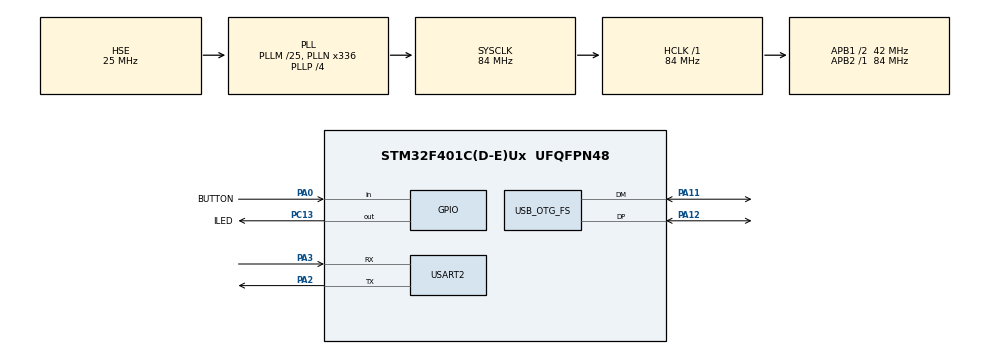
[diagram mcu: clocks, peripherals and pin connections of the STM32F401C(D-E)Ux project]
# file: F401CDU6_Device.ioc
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Dma.Request0=USART2_TX
Dma.Request1=USART2_RX
Dma.USART2_RX.1.Direction=DMA_PERIPH_TO_MEMORY
Dma.USART2_RX.1.FIFOMode=DMA_FIFOMODE_DISABLE
Dma.USART2_RX.1.Instance=DMA1_Stream5
Dma.USART2_RX.1.MemDataAlignment=DMA_MDATAALIGN_BYTE
Dma.USART2_RX.1.MemInc=DMA_MINC_ENABLE
Dma.USART2_RX.1.Mode=DMA_NORMAL
Dma.USART2_RX.1.PeriphDataAlignment=DMA_PDATAALIGN_BYTE
Dma.USART2_RX.1.PeriphInc=DMA_PINC_DISABLE
Dma.USART2_RX.1.Priority=DMA_PRIORITY_VERY_HIGH
Dma.USART2_TX.0.Direction=DMA_MEMORY_TO_PERIPH
Dma.USART2_TX.0.FIFOMode=DMA_FIFOMODE_DISABLE
Dma.USART2_TX.0.Instance=DMA1_Stream6
Dma.USART2_TX.0.MemDataAlignment=DMA_MDATAALIGN_BYTE
Dma.USART2_TX.0.MemInc=DMA_MINC_ENABLE
Dma.USART2_TX.0.Mode=DMA_NORMAL
Dma.USART2_TX.0.PeriphDataAlignment=DMA_PDATAALIGN_BYTE
Dma.USART2_TX.0.PeriphInc=DMA_PINC_DISABLE
Dma.USART2_TX.0.Priority=DMA_PRIORITY_VERY_HIGH
Mcu.Family=STM32F4
Mcu.Name=STM32F401C(D-E)Ux
Mcu.Package=UFQFPN48
NVIC.DMA1_Stream5_IRQn=true\:0\:0\:false\:false\:true\:false\:true\:true
NVIC.DMA1_Stream6_IRQn=true\:0\:0\:false\:false\:true\:false\:true\:true
NVIC.PriorityGroup=NVIC_PRIORITYGROUP_4
NVIC.USART2_IRQn=true\:0\:0\:false\:false\:true\:true\:true\:true
PA0-WKUP.GPIO_Label=BUTTON
PA0-WKUP.Signal=GPIO_Input
PA11.Mode=Device_Only
PA11.Signal=USB_OTG_FS_DM
PA12.Mode=Device_Only
PA12.Signal=USB_OTG_FS_DP
PA13.Mode=Serial_Wire
PA13.Signal=SYS_JTMS-SWDIO
PA14.Mode=Serial_Wire
PA14.Signal=SYS_JTCK-SWCLK
PA2.Mode=Asynchronous
PA2.Signal=USART2_TX
PA3.Mode=Asynchronous
PA3.Signal=USART2_RX
PC13-ANTI_TAMP.GPIO_Label=ILED
PC13-ANTI_TAMP.PinState=GPIO_PIN_SET
PC13-ANTI_TAMP.Signal=GPIO_Output
PC14-OSC32_IN.Mode=LSE-External-Oscillator
PC14-OSC32_IN.Signal=RCC_OSC32_IN
PC15-OSC32_OUT.Mode=LSE-External-Oscillator
PC15-OSC32_OUT.Signal=RCC_OSC32_OUT
PH0\ -\ OSC_IN.Mode=HSE-External-Oscillator
PH0\ -\ OSC_IN.Signal=RCC_OSC_IN
PH1\ -\ OSC_OUT.Mode=HSE-External-Oscillator
PH1\ -\ OSC_OUT.Signal=RCC_OSC_OUT
ProjectManager.HeapSize=0x200
ProjectManager.StackSize=0x400
ProjectManager.TargetToolchain=STM32CubeIDE
RCC.48MHZClocksFreq_Value=48000000
RCC.AHBFreq_Value=84000000
RCC.APB1CLKDivider=RCC_HCLK_DIV2
RCC.APB1Freq_Value=42000000
RCC.APB1TimFreq_Value=84000000
RCC.APB2Freq_Value=84000000
RCC.APB2TimFreq_Value=84000000
RCC.CortexFreq_Value=84000000
RCC.HCLKFreq_Value=84000000
RCC.HSE_VALUE=25000000
RCC.HSI_VALUE=16000000
RCC.PLLM=25
RCC.PLLN=336
RCC.PLLP=RCC_PLLP_DIV4
RCC.PLLQ=7
RCC.SYSCLKFreq_VALUE=84000000
RCC.SYSCLKSource=RCC_SYSCLKSOURCE_PLLCLK
RCC.VCOOutputFreq_Value=336000000
USART2.VirtualMode=VM_ASYNC
USB_OTG_FS.VirtualMode=Device_Only
VP_CRC_VS_CRC.Mode=CRC_Activate
board=custom

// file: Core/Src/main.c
/* USER CODE BEGIN Header */
/**
  ******************************************************************************
  * @file           : main.c
  * @brief          : Main program body
  ******************************************************************************
  * @attention
  *
  * Copyright (c) 2023 STMicroelectronics.
  * All rights reserved.
  *
  * This software is licensed under terms that can be found in the LICENSE file
  * in the root directory of this software component.
  * If no LICENSE file comes with this software, it is provided AS-IS.
  *
  ******************************************************************************
  */
/* USER CODE END Header */
#include "main.h"

/* USER CODE BEGIN Includes */
#define LED_OFF() HAL_GPIO_WritePin(ILED_GPIO_Port, ILED_Pin,GPIO_PIN_SET);
#define LED_ON() HAL_GPIO_WritePin(ILED_GPIO_Port, ILED_Pin,GPIO_PIN_RESET);
/* USER CODE END Includes */

/* USER CODE BEGIN PTD */
uint8_t my_uart2_redata=0;
/* USER CODE END PTD */

CRC_HandleTypeDef hcrc;

UART_HandleTypeDef huart2;
DMA_HandleTypeDef hdma_usart2_tx;
DMA_HandleTypeDef hdma_usart2_rx;

PCD_HandleTypeDef hpcd_USB_OTG_FS;

void SystemClock_Config(void);
static void MX_GPIO_Init(void);
static void MX_DMA_Init(void);
static void MX_CRC_Init(void);
static void MX_USART2_UART_Init(void);
static void MX_USB_OTG_FS_PCD_Init(void);

int main(void)
{

  /* MCU Configuration--------------------------------------------------------*/

  /* Reset of all peripherals, Initializes the Flash interface and the Systick. */
  HAL_Init();

  /* Configure the system clock */
  SystemClock_Config();

  /* Initialize all configured peripherals */
  MX_GPIO_Init();
  MX_DMA_Init();
  MX_CRC_Init();
  MX_USART2_UART_Init();
  MX_USB_OTG_FS_PCD_Init();
  /* USER CODE BEGIN 2 */
  HAL_UART_Receive_IT(&huart2, &my_uart2_redata, 1);
  /* USER CODE END 2 */

  /* Infinite loop */
  /* USER CODE BEGIN WHILE */
  while (1)
  {
	u_send("OK");
    /* USER CODE END WHILE */

  }
}

void SystemClock_Config(void)
{
  RCC_OscInitTypeDef RCC_OscInitStruct = {0};
  RCC_ClkInitTypeDef RCC_ClkInitStruct = {0};

  /** Configure the main internal regulator output voltage
  */
  __HAL_RCC_PWR_CLK_ENABLE();
  __HAL_PWR_VOLTAGESCALING_CONFIG(PWR_REGULATOR_VOLTAGE_SCALE2);

  /** Initializes the RCC Oscillators according to the specified parameters
  * in the RCC_OscInitTypeDef structure.
  */
  RCC_OscInitStruct.OscillatorType = RCC_OSCILLATORTYPE_HSE;
  RCC_OscInitStruct.HSEState = RCC_HSE_ON;
  RCC_OscInitStruct.PLL.PLLState = RCC_PLL_ON;
  RCC_OscInitStruct.PLL.PLLSource = RCC_PLLSOURCE_HSE;
  RCC_OscInitStruct.PLL.PLLM = 25;
  RCC_OscInitStruct.PLL.PLLN = 336;
  RCC_OscInitStruct.PLL.PLLP = RCC_PLLP_DIV4;
  RCC_OscInitStruct.PLL.PLLQ = 7;
  if (HAL_RCC_OscConfig(&RCC_OscInitStruct) != HAL_OK)
  {
    Error_Handler();
  }

  /** Initializes the CPU, AHB and APB buses clocks
  */
  RCC_ClkInitStruct.ClockType = RCC_CLOCKTYPE_HCLK|RCC_CLOCKTYPE_SYSCLK
                              |RCC_CLOCKTYPE_PCLK1|RCC_CLOCKTYPE_PCLK2;
  RCC_ClkInitStruct.SYSCLKSource = RCC_SYSCLKSOURCE_PLLCLK;
  RCC_ClkInitStruct.AHBCLKDivider = RCC_SYSCLK_DIV1;
  RCC_ClkInitStruct.APB1CLKDivider = RCC_HCLK_DIV2;
  RCC_ClkInitStruct.APB2CLKDivider = RCC_HCLK_DIV1;

  if (HAL_RCC_ClockConfig(&RCC_ClkInitStruct, FLASH_LATENCY_2) != HAL_OK)
  {
    Error_Handler();
  }
}

static void MX_CRC_Init(void)
{

  hcrc.Instance = CRC;
  if (HAL_CRC_Init(&hcrc) != HAL_OK)
  {
    Error_Handler();
  }

}

static void MX_USART2_UART_Init(void)
{

  huart2.Instance = USART2;
  huart2.Init.BaudRate = 115200;
  huart2.Init.WordLength = UART_WORDLENGTH_8B;
  huart2.Init.StopBits = UART_STOPBITS_1;
  huart2.Init.Parity = UART_PARITY_NONE;
  huart2.Init.Mode = UART_MODE_TX_RX;
  huart2.Init.HwFlowCtl = UART_HWCONTROL_NONE;
  huart2.Init.OverSampling = UART_OVERSAMPLING_16;
  if (HAL_UART_Init(&huart2) != HAL_OK)
  {
    Error_Handler();
  }

}

static void MX_USB_OTG_FS_PCD_Init(void)
{

  hpcd_USB_OTG_FS.Instance = USB_OTG_FS;
  hpcd_USB_OTG_FS.Init.dev_endpoints = 4;
  hpcd_USB_OTG_FS.Init.speed = PCD_SPEED_FULL;
  hpcd_USB_OTG_FS.Init.dma_enable = DISABLE;
  hpcd_USB_OTG_FS.Init.phy_itface = PCD_PHY_EMBEDDED;
  hpcd_USB_OTG_FS.Init.Sof_enable = DISABLE;
  hpcd_USB_OTG_FS.Init.low_power_enable = DISABLE;
  hpcd_USB_OTG_FS.Init.lpm_enable = DISABLE;
  hpcd_USB_OTG_FS.Init.vbus_sensing_enable = DISABLE;
  hpcd_USB_OTG_FS.Init.use_dedicated_ep1 = DISABLE;
  if (HAL_PCD_Init(&hpcd_USB_OTG_FS) != HAL_OK)
  {
    Error_Handler();
  }

}

static void MX_DMA_Init(void)
{

  /* DMA controller clock enable */
  __HAL_RCC_DMA1_CLK_ENABLE();

  /* DMA interrupt init */
  /* DMA1_Stream5_IRQn interrupt configuration */
  HAL_NVIC_SetPriority(DMA1_Stream5_IRQn, 0, 0);
  HAL_NVIC_EnableIRQ(DMA1_Stream5_IRQn);
  /* DMA1_Stream6_IRQn interrupt configuration */
  HAL_NVIC_SetPriority(DMA1_Stream6_IRQn, 0, 0);
  HAL_NVIC_EnableIRQ(DMA1_Stream6_IRQn);

}

static void MX_GPIO_Init(void)
{
  GPIO_InitTypeDef GPIO_InitStruct = {0};

  /* GPIO Ports Clock Enable */
  __HAL_RCC_GPIOC_CLK_ENABLE();
  __HAL_RCC_GPIOH_CLK_ENABLE();
  __HAL_RCC_GPIOA_CLK_ENABLE();

  /*Configure GPIO pin Output Level */
  HAL_GPIO_WritePin(ILED_GPIO_Port, ILED_Pin, GPIO_PIN_SET);

  /*Configure GPIO pin : ILED_Pin */
  GPIO_InitStruct.Pin = ILED_Pin;
  GPIO_InitStruct.Mode = GPIO_MODE_OUTPUT_PP;
  GPIO_InitStruct.Pull = GPIO_NOPULL;
  GPIO_InitStruct.Speed = GPIO_SPEED_FREQ_LOW;
  HAL_GPIO_Init(ILED_GPIO_Port, &GPIO_InitStruct);

  /*Configure GPIO pin : BUTTON_Pin */
  GPIO_InitStruct.Pin = BUTTON_Pin;
  GPIO_InitStruct.Mode = GPIO_MODE_INPUT;
  GPIO_InitStruct.Pull = GPIO_NOPULL;
  HAL_GPIO_Init(BUTTON_GPIO_Port, &GPIO_InitStruct);

}

/* USER CODE BEGIN 4 */
void HAL_UART_RxCpltCallback(UART_HandleTypeDef *huart){
    //if(huart->Instance == USART2)
    //{
    	LED_ON();
    	u_send("RECV\r\n");
    	LED_OFF();
    //}
}

void u_send(uint8_t *tdata){
	while(HAL_DMA_GetState(&hdma_usart2_tx) == HAL_DMA_STATE_BUSY) HAL_Delay(1);
	HAL_UART_Transmit_DMA(&huart2, tdata, sizeof(tdata)/sizeof(tdata[0]));
}
/* USER CODE END 4 */

void Error_Handler(void)
{
  __disable_irq();
  while (1)
  {
  }
}
